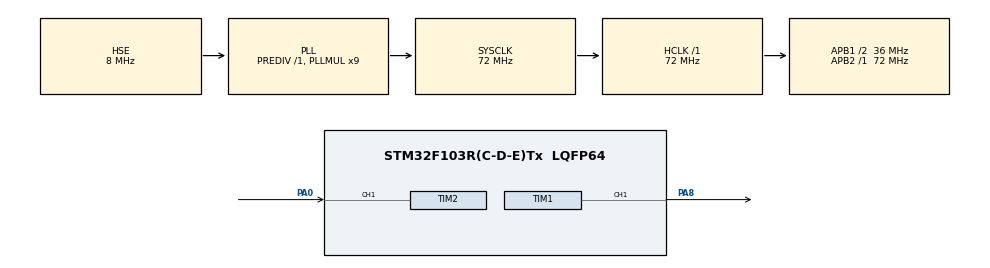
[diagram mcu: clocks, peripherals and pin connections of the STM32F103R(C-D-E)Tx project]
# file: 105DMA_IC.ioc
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Dma.Request0=TIM2_CH1
Dma.Request1=TIM2_CH2/CH4
Dma.TIM2_CH1.0.Direction=DMA_PERIPH_TO_MEMORY
Dma.TIM2_CH1.0.Instance=DMA1_Channel5
Dma.TIM2_CH1.0.MemDataAlignment=DMA_MDATAALIGN_HALFWORD
Dma.TIM2_CH1.0.MemInc=DMA_MINC_ENABLE
Dma.TIM2_CH1.0.Mode=DMA_NORMAL
Dma.TIM2_CH1.0.PeriphDataAlignment=DMA_PDATAALIGN_HALFWORD
Dma.TIM2_CH1.0.PeriphInc=DMA_PINC_DISABLE
Dma.TIM2_CH1.0.Priority=DMA_PRIORITY_LOW
Dma.TIM2_CH2/CH4.1.Direction=DMA_PERIPH_TO_MEMORY
Dma.TIM2_CH2/CH4.1.Instance=DMA1_Channel7
Dma.TIM2_CH2/CH4.1.MemDataAlignment=DMA_MDATAALIGN_WORD
Dma.TIM2_CH2/CH4.1.MemInc=DMA_MINC_ENABLE
Dma.TIM2_CH2/CH4.1.Mode=DMA_CIRCULAR
Dma.TIM2_CH2/CH4.1.PeriphDataAlignment=DMA_PDATAALIGN_WORD
Dma.TIM2_CH2/CH4.1.PeriphInc=DMA_PINC_DISABLE
Dma.TIM2_CH2/CH4.1.Priority=DMA_PRIORITY_LOW
Mcu.Family=STM32F1
Mcu.Name=STM32F103R(C-D-E)Tx
Mcu.Package=LQFP64
NVIC.DMA1_Channel5_IRQn=true\:0\:0\:false\:false\:true\:false\:true
NVIC.DMA1_Channel7_IRQn=true\:0\:0\:false\:false\:true\:false\:true
NVIC.PriorityGroup=NVIC_PRIORITYGROUP_4
PA0-WKUP.Signal=S_TIM2_CH1_ETR
PA13.Mode=Serial_Wire
PA13.Signal=SYS_JTMS-SWDIO
PA14.Mode=Serial_Wire
PA14.Signal=SYS_JTCK-SWCLK
PA8.Signal=S_TIM1_CH1
PD0-OSC_IN.Mode=HSE-External-Oscillator
PD0-OSC_IN.Signal=RCC_OSC_IN
PD1-OSC_OUT.Mode=HSE-External-Oscillator
PD1-OSC_OUT.Signal=RCC_OSC_OUT
ProjectManager.HeapSize=0x200
ProjectManager.StackSize=0x400
ProjectManager.TargetToolchain=MDK-ARM V5.27
RCC.AHBFreq_Value=72000000
RCC.APB1CLKDivider=RCC_HCLK_DIV2
RCC.APB1Freq_Value=36000000
RCC.APB1TimFreq_Value=72000000
RCC.APB2Freq_Value=72000000
RCC.APB2TimFreq_Value=72000000
RCC.HCLKFreq_Value=72000000
RCC.PLLMUL=RCC_PLL_MUL9
RCC.PLLSourceVirtual=RCC_PLLSOURCE_HSE
RCC.SYSCLKFreq_VALUE=72000000
RCC.SYSCLKSource=RCC_SYSCLKSOURCE_PLLCLK
RCC.USBFreq_Value=72000000
SH.S_TIM1_CH1.0=TIM1_CH1,PWM Generation1 CH1
SH.S_TIM2_CH1_ETR.0=TIM2_CH1,TriggerSource_TI1FP1
SH.S_TIM2_CH1_ETR.1=TIM2_CH1,Input_Capture1_from_TI1
SH.S_TIM2_CH1_ETR.2=TIM2_CH1,Input_Capture2_from_TI1
TIM1.Channel-PWM\ Generation1\ CH1=TIM_CHANNEL_1
TIM1.Period=10000-1
TIM1.Prescaler=72-1
TIM1.Pulse-PWM\ Generation1\ CH1=5000-1
TIM2.Channel-Input_Capture1_from_TI1=TIM_CHANNEL_1
TIM2.Channel-Input_Capture2_from_TI1=TIM_CHANNEL_2
TIM2.ICPolarity_CH2=TIM_INPUTCHANNELPOLARITY_FALLING
TIM2.Period=65536-1
TIM2.Prescaler=72-1
TIM2.TIM_MasterSlaveMode=TIM_MASTERSLAVEMODE_ENABLE
VP_TIM1_VS_ClockSourceINT.Mode=Internal
VP_TIM2_VS_ClockSourceINT.Mode=Internal
VP_TIM2_VS_ControllerModeReset.Mode=Reset Mode
board=custom

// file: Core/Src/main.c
/* USER CODE BEGIN Header */
/**
  ******************************************************************************
  * @file           : main.c
  * @brief          : Main program body
  ******************************************************************************
  * @attention
  *
  * <h2><center>&copy; Copyright (c) 2021 STMicroelectronics.
  * All rights reserved.</center></h2>
  *
  * This software component is licensed by ST under BSD 3-Clause license,
  * the "License"; You may not use this file except in compliance with the
  * License. You may obtain a copy of the License at:
  *                        opensource.org/licenses/BSD-3-Clause
  *
  ******************************************************************************
  */
/* USER CODE END Header */
#include "main.h"
#include "dma.h"
#include "tim.h"
#include "gpio.h"

void SystemClock_Config(void);

/* USER CODE BEGIN 0 */
uint32_t PWM_Period = 0, PWM_Duty = 0;
/* USER CODE END 0 */

int main(void)
{

  /* MCU Configuration--------------------------------------------------------*/

  /* Reset of all peripherals, Initializes the Flash interface and the Systick. */
  HAL_Init();

  /* Configure the system clock */
  SystemClock_Config();

  /* Initialize all configured peripherals */
  MX_GPIO_Init();
  MX_DMA_Init();
  MX_TIM2_Init();
  MX_TIM1_Init();
  /* USER CODE BEGIN 2 */
  HAL_TIM_Base_Start(&htim1);
  HAL_TIM_PWM_Start(&htim1, TIM_CHANNEL_1);

  HAL_TIM_Base_Start(&htim2);
  HAL_TIM_IC_Start_DMA(&htim2, TIM_CHANNEL_1,&PWM_Period,1);
  htim2.State = HAL_TIM_STATE_READY;
  HAL_TIM_IC_Start_DMA(&htim2, TIM_CHANNEL_2,&PWM_Duty,1);
  /* USER CODE END 2 */

  /* Infinite loop */
  while (1)
  {

  }
}

void SystemClock_Config(void)
{
  RCC_OscInitTypeDef RCC_OscInitStruct = {0};
  RCC_ClkInitTypeDef RCC_ClkInitStruct = {0};

  /** Initializes the RCC Oscillators according to the specified parameters
  * in the RCC_OscInitTypeDef structure.
  */
  RCC_OscInitStruct.OscillatorType = RCC_OSCILLATORTYPE_HSE;
  RCC_OscInitStruct.HSEState = RCC_HSE_ON;
  RCC_OscInitStruct.HSEPredivValue = RCC_HSE_PREDIV_DIV1;
  RCC_OscInitStruct.HSIState = RCC_HSI_ON;
  RCC_OscInitStruct.PLL.PLLState = RCC_PLL_ON;
  RCC_OscInitStruct.PLL.PLLSource = RCC_PLLSOURCE_HSE;
  RCC_OscInitStruct.PLL.PLLMUL = RCC_PLL_MUL9;
  if (HAL_RCC_OscConfig(&RCC_OscInitStruct) != HAL_OK)
  {
    Error_Handler();
  }
  /** Initializes the CPU, AHB and APB buses clocks
  */
  RCC_ClkInitStruct.ClockType = RCC_CLOCKTYPE_HCLK|RCC_CLOCKTYPE_SYSCLK
                              |RCC_CLOCKTYPE_PCLK1|RCC_CLOCKTYPE_PCLK2;
  RCC_ClkInitStruct.SYSCLKSource = RCC_SYSCLKSOURCE_PLLCLK;
  RCC_ClkInitStruct.AHBCLKDivider = RCC_SYSCLK_DIV1;
  RCC_ClkInitStruct.APB1CLKDivider = RCC_HCLK_DIV2;
  RCC_ClkInitStruct.APB2CLKDivider = RCC_HCLK_DIV1;

  if (HAL_RCC_ClockConfig(&RCC_ClkInitStruct, FLASH_LATENCY_2) != HAL_OK)
  {
    Error_Handler();
  }
}

void Error_Handler(void)
{
  __disable_irq();
  while (1)
  {
  }
}

/************************ (C) COPYRIGHT STMicroelectronics *****END OF FILE****/
